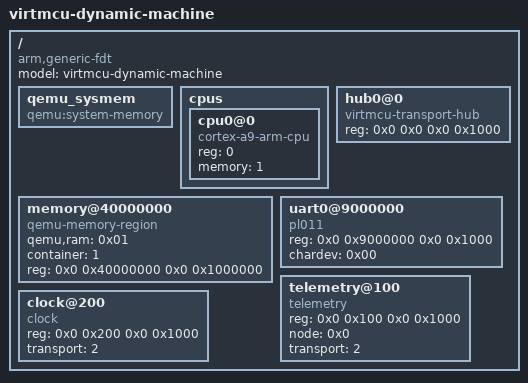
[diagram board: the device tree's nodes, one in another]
/dts-v1/;

/ {
    model = "virtmcu-dynamic-machine";
    compatible = "arm,generic-fdt";
    #address-cells = <2>;
    #size-cells = <2>;

    qemu_sysmem: qemu_sysmem {
        compatible = "qemu:system-memory";
        phandle = <1>;
    };

    cpus {
        #address-cells = <1>;
        #size-cells = <0>;
        cpu0@0 {
            device_type = "cpu";
            compatible = "cortex-a9-arm-cpu";
            reg = <0>;
            memory = <1>;
        };
    };

    hub0@0 {
        compatible = "virtmcu-transport-hub";
        phandle = <2>;
        reg = <0x0 0x0 0x0 0x1000>;
    };
    memory@40000000 {
        compatible = "qemu-memory-region";
        qemu,ram = <0x01>;
        container = <1>;
        reg = <0x0 0x40000000 0x0 0x1000000>;
    };
    uart0@9000000 {
        compatible = "pl011";
        phandle = <5>;
        reg = <0x0 0x9000000 0x0 0x1000>;
        chardev = <0x00>;
    };
    telemetry@100 {
        compatible = "telemetry";
        phandle = <6>;
        reg = <0x0 0x100 0x0 0x1000>;
        node = <0x0>;
        transport = <2>;
    };
    clock@200 {
        compatible = "clock";
        phandle = <7>;
        reg = <0x0 0x200 0x0 0x1000>;
        transport = <2>;
    };
};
